# AT91SAM9CN11 register map
Vendor: Atmel; Series: SAM9CN; File version: 20130208
Registers are 32-bit, read-only, reset 0x0 unless marked. A register's access mark holds for its fields unless they carry their own. Offsets are from the block's base; [hi:lo] are bit positions; {n}, {i} and the like mark numbered series.

## LCDC — LCD Controller
Base 0xF8038000; register names take the prefix LCDC_
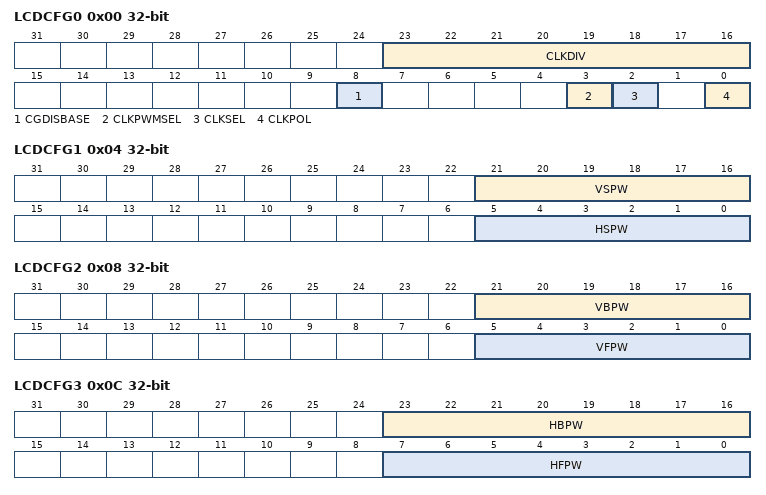
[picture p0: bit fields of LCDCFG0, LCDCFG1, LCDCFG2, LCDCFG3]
0x00 LCDCFG0 rw — LCD Controller Configuration Register 0
  [23:16] CLKDIV — LCD Controller Clock Divider
  [8] CGDISBASE — Clock Gating Disable Control for the Base Layer
  [3] CLKPWMSEL — LCD Controller PWM Clock Source Selection
  [2] CLKSEL — LCD Controller Clock Source Selection
  [0] CLKPOL — LCD Controller Clock Polarity
0x04 LCDCFG1 rw — LCD Controller Configuration Register 1
  [21:16] VSPW — Vertical Synchronization Pulse Width
  [5:0] HSPW — Horizontal Synchronization Pulse Width
0x08 LCDCFG2 rw — LCD Controller Configuration Register 2
  [21:16] VBPW — Vertical Back Porch Width
  [5:0] VFPW — Vertical Front Porch Width
0x0C LCDCFG3 rw — LCD Controller Configuration Register 3
  [23:16] HBPW — Horizontal Back Porch Width
  [7:0] HFPW — Horizontal Front Porch Width
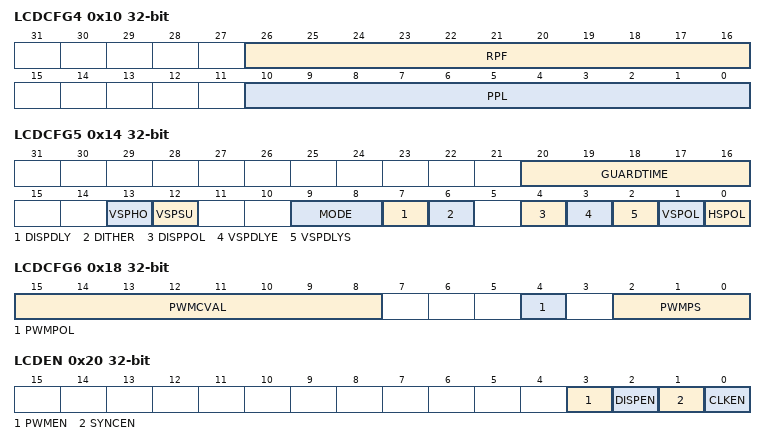
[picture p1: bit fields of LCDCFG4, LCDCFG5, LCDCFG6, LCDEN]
0x10 LCDCFG4 rw — LCD Controller Configuration Register 4
  [26:16] RPF — Number of Active Rows Per Frame
  [10:0] PPL — Number of Pixels Per Line
0x14 LCDCFG5 rw — LCD Controller Configuration Register 5
  [20:16] GUARDTIME — LCD DISPLAY Guard Time
  [13] VSPHO — LCD Controller Vertical Synchronization Pulse Hold Configuration
  [12] VSPSU — LCD Controller Vertical Synchronization Pulse Setup Configuration
  [9:8] MODE — LCD Controller Output Mode
    0=OUTPUT_12BPP (LCD output mode is set to 12 bits per pixel); 1=OUTPUT_16BPP (LCD output mode is set to 16 bits per pixel); 2=OUTPUT_18BPP (LCD output mode is set to 18 bits per pixel); 3=OUTPUT_24BPP (LCD output mode is set to 24 bits per pixel)
  [7] DISPDLY — LCD Controller Display Power Signal Synchronization
  [6] DITHER — LCD Controller Dithering
  [4] DISPPOL — Display Signal Polarity
  [3] VSPDLYE — Vertical Synchronization Pulse End
  [2] VSPDLYS — Vertical Synchronization Pulse Start
  [1] VSPOL — Vertical Synchronization Pulse Polarity
  [0] HSPOL — Horizontal Synchronization Pulse Polarity
0x18 LCDCFG6 rw — LCD Controller Configuration Register 6
  [15:8] PWMCVAL — LCD Controller PWM Compare Value
  [4] PWMPOL — LCD Controller PWM Signal Polarity
  [2:0] PWMPS — PWM Clock Prescaler
0x20 LCDEN wo reset not defined — LCD Controller Enable Register
  [3] PWMEN — LCD Controller Pulse Width Modulation Enable
  [2] DISPEN — LCD Controller DISP Signal Enable
  [1] SYNCEN — LCD Controller Horizontal and Vertical Synchronization Enable
  [0] CLKEN — LCD Controller Pixel Clock Enable
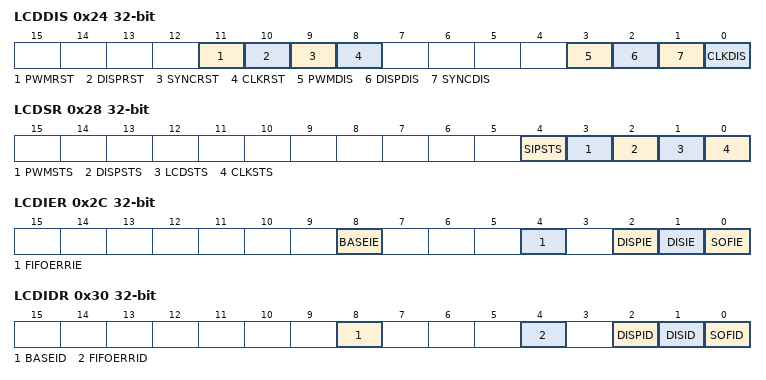
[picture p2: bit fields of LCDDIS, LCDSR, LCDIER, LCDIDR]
0x24 LCDDIS wo reset not defined — LCD Controller Disable Register
  [11] PWMRST — LCD Controller PWM Reset
  [10] DISPRST — LCD Controller DISP Signal Reset
  [9] SYNCRST — LCD Controller Horizontal and Vertical Synchronization Reset
  [8] CLKRST — LCD Controller Clock Reset
  [3] PWMDIS — LCD Controller Pulse Width Modulation Disable
  [2] DISPDIS — LCD Controller DISP Signal Disable
  [1] SYNCDIS — LCD Controller Horizontal and Vertical Synchronization Disable
  [0] CLKDIS — LCD Controller Pixel Clock Disable
0x28 LCDSR — LCD Controller Status Register
  [4] SIPSTS — Synchronization In Progress
  [3] PWMSTS — LCD Controller PWM Signal Status
  [2] DISPSTS — LCD Controller DISP Signal Status
  [1] LCDSTS — LCD Controller Synchronization status
  [0] CLKSTS — Clock Status
0x2C LCDIER wo reset not defined — LCD Controller Interrupt Enable Register
  [8] BASEIE — Base Layer Interrupt Enable Register
  [4] FIFOERRIE — Output FIFO Error Interrupt Enable Register
  [2] DISPIE — Power UP/Down Sequence Terminated Interrupt Enable Register
  [1] DISIE — LCD Disable Interrupt Enable Register
  [0] SOFIE — Start of Frame Interrupt Enable Register
0x30 LCDIDR wo reset not defined — LCD Controller Interrupt Disable Register
  [8] BASEID — Base Layer Interrupt Disable Register
  [4] FIFOERRID — Output FIFO Error Interrupt Disable Register
  [2] DISPID — Power UP/Down Sequence Terminated Interrupt Disable Register
  [1] DISID — LCD Disable Interrupt Disable Register
  [0] SOFID — Start of Frame Interrupt Disable Register
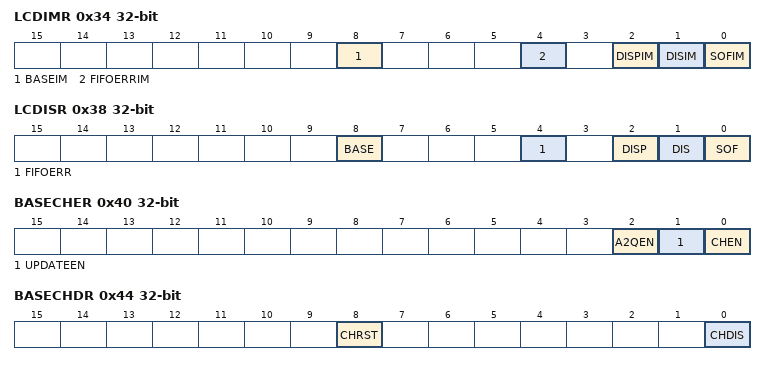
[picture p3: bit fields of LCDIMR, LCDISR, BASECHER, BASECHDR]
0x34 LCDIMR — LCD Controller Interrupt Mask Register
  [8] BASEIM — Base Layer Interrupt Mask Register
  [4] FIFOERRIM — Output FIFO Error Interrupt Mask Register
  [2] DISPIM — Power UP/Down Sequence Terminated Interrupt Mask Register
  [1] DISIM — LCD Disable Interrupt Mask Register
  [0] SOFIM — Start of Frame Interrupt Mask Register
0x38 LCDISR — LCD Controller Interrupt Status Register
  [8] BASE — Base Layer Raw Interrupt Status Register
  [4] FIFOERR — Output FIFO Error
  [2] DISP — Power-up/Power-down Sequence Terminated Interrupt Status Register
  [1] DIS — LCD Disable Interrupt Status Register
  [0] SOF — Start of Frame Interrupt Status Register
0x40 BASECHER wo — Base Layer Channel Enable Register
  [2] A2QEN — Add Head Pointer Enable Register
  [1] UPDATEEN — Update Overlay Attributes Enable Register
  [0] CHEN — Channel Enable Register
0x44 BASECHDR wo — Base Layer Channel Disable Register
  [8] CHRST — Channel Reset Register
  [0] CHDIS — Channel Disable Register
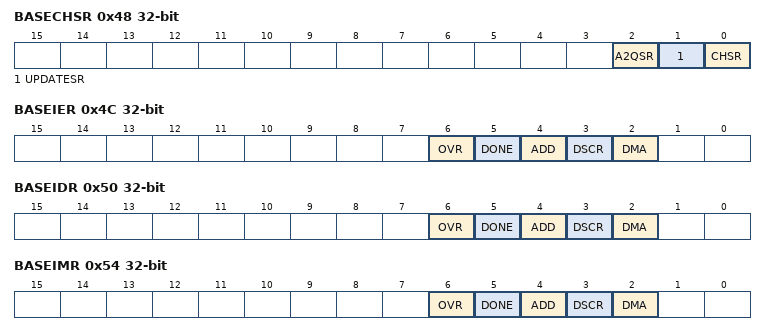
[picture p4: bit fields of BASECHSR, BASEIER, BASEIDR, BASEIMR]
0x48 BASECHSR — Base Layer Channel Status Register
  [2] A2QSR — Add To Queue Pending Register
  [1] UPDATESR — Update Overlay Attributes In Progress
  [0] CHSR — Channel Status Register
0x4C BASEIER wo — Base Layer Interrupt Enable Register
  [6] OVR — Overflow Interrupt Enable Register
  [5] DONE — End of List Interrupt Enable Register
  [4] ADD — Head Descriptor Loaded Interrupt Enable Register
  [3] DSCR — Descriptor Loaded Interrupt Enable Register
  [2] DMA — End of DMA Transfer Interrupt Enable Register
0x50 BASEIDR wo — Base Layer Interrupt Disabled Register
  [6] OVR — Overflow Interrupt Disable Register
  [5] DONE — End of List Interrupt Disable Register
  [4] ADD — Head Descriptor Loaded Interrupt Disable Register
  [3] DSCR — Descriptor Loaded Interrupt Disable Register
  [2] DMA — End of DMA Transfer Interrupt Disable Register
0x54 BASEIMR — Base Layer Interrupt Mask Register
  [6] OVR — Overflow Interrupt Mask Register
  [5] DONE — End of List Interrupt Mask Register
  [4] ADD — Head Descriptor Loaded Interrupt Mask Register
  [3] DSCR — Descriptor Loaded Interrupt Mask Register
  [2] DMA — End of DMA Transfer Interrupt Mask Register
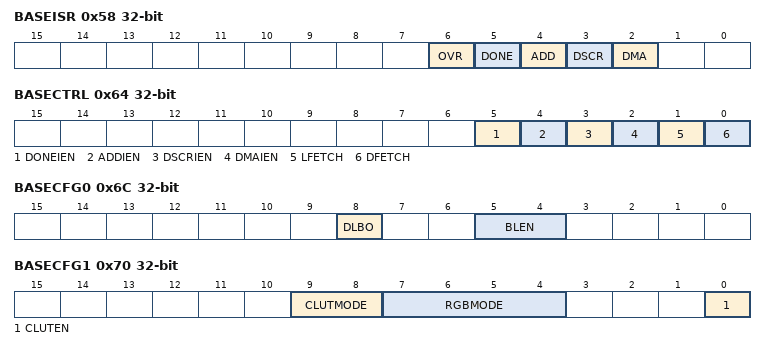
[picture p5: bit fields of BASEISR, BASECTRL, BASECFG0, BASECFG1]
0x58 BASEISR — Base Layer Interrupt status Register
  [6] OVR — Overflow Detected
  [5] DONE — End of List Detected
  [4] ADD — Head Descriptor Loaded
  [3] DSCR — DMA Descriptor Loaded
  [2] DMA — End of DMA Transfer
0x5C BASEHEAD rw — Base Layer DMA Head Register
  [31:2] HEAD — DMA Head Pointer
0x60 BASEADDR rw — Base Layer DMA Address Register
  [31:0] ADDR — DMA Transfer Start Address
0x64 BASECTRL rw — Base Layer DMA Control Register
  [5] DONEIEN — End of List Interrupt Enable
  [4] ADDIEN — Add Head Descriptor to Queue Interrupt Enable
  [3] DSCRIEN — Descriptor Loaded Interrupt Enable
  [2] DMAIEN — End of DMA Transfer Interrupt Enable
  [1] LFETCH — Lookup Table Fetch Enable
  [0] DFETCH — Transfer Descriptor Fetch Enable
0x68 BASENEXT rw — Base Layer DMA Next Register
  [31:0] NEXT — DMA Descriptor Next Address
0x6C BASECFG0 rw — Base Layer Configuration Register 0
  [8] DLBO — Defined Length Burst Only For Channel Bus Transaction.
  [5:4] BLEN — AHB Burst Length
    0=AHB_SINGLE (AHB Access is started as soon as there is enough space in the FIFO to store one 32-bit data. SINGLE, INCR, INCR4, INCR8 and INCR16 bursts can be used. INCR is used for a burst of 2 and 3 beats.); 1=AHB_INCR4 (AHB Access is started as soon as there is enough space in the FIFO to store a total amount of four 32-bit data. An AHB INCR4 Burst is preferred. SINGLE, INCR and INCR4 bursts can be used. INCR is used for a burst of 2 and 3 beats.); 2=AHB_INCR8 (AHB Access is started as soon as there is enough space in the FIFO to store a total amount of eight 32-bit data. An AHB INCR8 Burst is preferred. SINGLE, INCR, INCR4 and INCR8 bursts can be used. INCR is used for a burst of 2 and 3 beats.); 3=AHB_INCR16 (AHB Access is started as soon as there is enough space in the FIFO to store a total amount of sixteen 32-bit data. An AHB INCR16 Burst is preferred. SINGLE, INCR, INCR4, INCR8 and INCR16 bursts can be used. INCR is used for a burst of 2 and 3 beats.)
0x70 BASECFG1 rw — Base Layer Configuration Register 1
  [9:8] CLUTMODE — Color Lookup Table Input Mode Selection
    0=1BPP (color lookup table mode set to 1 bit per pixel); 1=2BPP (color lookup table mode set to 2 bits per pixel); 2=4BPP (color lookup table mode set to 4 bits per pixel); 3=8BPP (color lookup table mode set to 8 bits per pixel)
  [7:4] RGBMODE — RGB Input Mode Selection
    0=12BPP_RGB_444; 1=16BPP_ARGB_4444; 2=16BPP_RGBA_4444; 3=16BPP_RGB_565; 4=16BPP_TRGB_1555; 5=18BPP_RGB_666; 6=18BPP_RGB_666_PACKED; 7=19BPP_TRGB_1666; 8=19BPP_TRGB_PACKED (19 bpp TRGB 1666 PACKED); 9=24BPP_RGB_888; 10=24BPP_RGB_888_PACKED; 11=25BPP_TRGB_1888; 12=32BPP_ARGB_8888; 13=32BPP_RGBA_8888
  [0] CLUTEN — Color Lookup Table Enable
0x74 BASECFG2 rw — Base Layer Configuration Register 2
  [31:0] XSTRIDE — Horizontal Stride
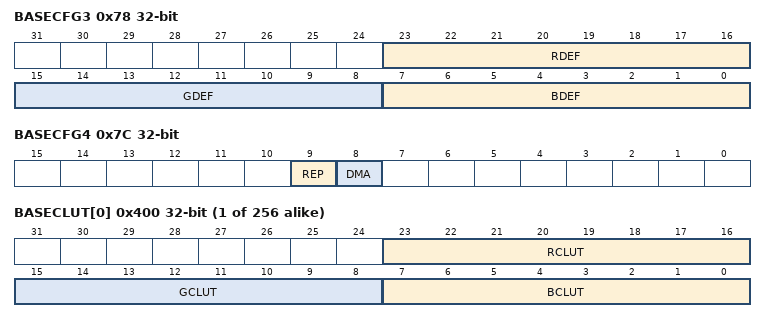
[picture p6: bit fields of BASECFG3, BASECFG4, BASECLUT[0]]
0x78 BASECFG3 rw — Base Layer Configuration Register 3
  [23:16] RDEF — Red Default
  [15:8] GDEF — Green Default
  [7:0] BDEF — Blue Default
0x7C BASECFG4 rw — Base Layer Configuration Register 4
  [9] REP — Use Replication logic to expand RGB color to 24 bits
  [8] DMA — Use DMA Data Path
{0x400+4i} BASECLUT[{i}] (i=0..255) rw reset not defined
  [23:16] RCLUT — Red Color entry
  [15:8] GCLUT — Green Color entry
  [7:0] BCLUT — Blue Color entry
0x1FEC ADDRSIZE reset not defined — Address Size Register
{0x1FF0+4i} IPNAME[{i}] (i=0..1) reset not defined — IP Name1 Register
0x1FF8 FEATURES reset not defined
0x1FFC VERSION reset not defined
